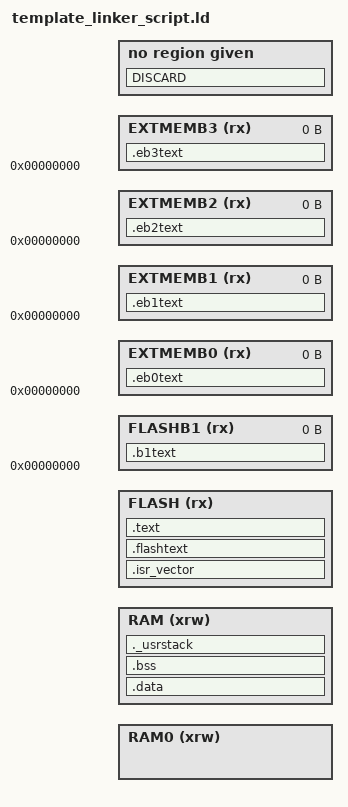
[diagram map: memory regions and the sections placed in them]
__flash         = @FLASH_ORIGIN@;
__flash_size    = @FLASH_SIZE@K;
__ram           = @RAM_ORIGIN@;
__ram_size      = @RAM_SIZE@K;
__isr_ram_size  = @ISR_RAM_SIZE@;
__stack_size    = @STACK_SIZE@;
__heap_size_min = @HEAP_MIN@;

_estack  = __ram + __ram_size;
RAM0     = __ram;
RAM0_SIZ = __isr_ram_size;
RAM      = __ram + __isr_ram_size;
RAM_SIZ  = __ram_size - __isr_ram_size;

/* Entry Point */
ENTRY(Reset_Handler)

_Minimum_Stack_Size = __stack_size;


/* Memory Spaces Definitions */
MEMORY
{
    RAM0 (xrw) : ORIGIN = RAM0,    LENGTH = RAM0_SIZ
    RAM (xrw)  : ORIGIN = RAM,     LENGTH = RAM_SIZ
    FLASH (rx) : ORIGIN = __flash, LENGTH = __flash_size
    FLASHB1 (rx) : ORIGIN = 0x00000000, LENGTH = 0
    EXTMEMB0 (rx) : ORIGIN = 0x00000000, LENGTH = 0
    EXTMEMB1 (rx) : ORIGIN = 0x00000000, LENGTH = 0
    EXTMEMB2 (rx) : ORIGIN = 0x00000000, LENGTH = 0
    EXTMEMB3 (rx) : ORIGIN = 0x00000000, LENGTH = 0
}

/* Sections Definitions */
SECTIONS
{
    /* for Cortex devices, the beginning of the startup code is stored in the .isr_vector section, which goes to FLASH */
    .isr_vector :
    {
	. = ALIGN(4);
        KEEP(*(.isr_vector))            /* Startup code */
	. = ALIGN(4);
    } >FLASH
 
    /* for some STRx devices, the beginning of the startup code is stored in the .flashtext section, which goes to FLASH */
    .flashtext :
    {
	. = ALIGN(4);
        *(.flashtext)            /* Startup code */
	. = ALIGN(4);
    } >FLASH
 
    
    /* the program code is stored in the .text section, which goes to Flash */
    .text :
    {
	    . = ALIGN(4);
	    
        *(.text)                   /* remaining code */
        *(.text.*)                   /* remaining code */
        *(.rodata)                 /* read-only data (constants) */
        *(.rodata*)
        *(.glue_7)
        *(.glue_7t)

	    . = ALIGN(4);
   	 _etext = .;
	    /* This is used by the startup in order to initialize the .data secion */
   	 _sidata = _etext;
    } >FLASH
    
 

    /* This is the initialized data section
    The program executes knowing that the data is in the RAM
    but the loader puts the initial values in the FLASH (inidata).
    It is one task of the startup to copy the initial values from FLASH to RAM. */
    .data  : AT ( _sidata )
    {
	    . = ALIGN(4);
        /* This is used by the startup in order to initialize the .data secion */
        _sdata = . ;
        
        *(.data)
        *(.data.*)

	    . = ALIGN(4);
	    /* This is used by the startup in order to initialize the .data secion */
   	 _edata = . ;
    } >RAM
    
    

    /* This is the uninitialized data section */
    .bss :
    {
	    . = ALIGN(4);
        /* This is used by the startup in order to initialize the .bss secion */
        _sbss = .;
        
        *(.bss)
        *(COMMON)
        
	    . = ALIGN(4);
	    /* This is used by the startup in order to initialize the .bss secion */
   	 _ebss = . ;
    } >RAM
    
    PROVIDE ( end = _ebss );
    PROVIDE ( _end = _ebss );
    
    /* This is the user stack section 
    This is just to check that there is enough RAM left for the User mode stack
    It should generate an error if it's full.
     */
    ._usrstack :
    {
	    . = ALIGN(4);
        _susrstack = . ;
        
        . = . + _Minimum_Stack_Size ;
        
	    . = ALIGN(4);
        _eusrstack = . ;
    } >RAM
    

   
    /* this is the FLASH Bank1 */
    /* the C or assembly source must explicitly place the code or data there
    using the "section" attribute */
    .b1text :
    {
        *(.b1text)                   /* remaining code */
        *(.b1rodata)                 /* read-only data (constants) */
        *(.b1rodata*)
    } >FLASHB1
    
    /* this is the EXTMEM */
    /* the C or assembly source must explicitly place the code or data there
    using the "section" attribute */
    
    /* EXTMEM Bank0 */
    .eb0text :
    {
        *(.eb0text)                   /* remaining code */
        *(.eb0rodata)                 /* read-only data (constants) */
        *(.eb0rodata*)
    } >EXTMEMB0
    
    /* EXTMEM Bank1 */
    .eb1text :
    {
        *(.eb1text)                   /* remaining code */
        *(.eb1rodata)                 /* read-only data (constants) */
        *(.eb1rodata*)
    } >EXTMEMB1
    
    /* EXTMEM Bank2 */
    .eb2text :
    {
        *(.eb2text)                   /* remaining code */
        *(.eb2rodata)                 /* read-only data (constants) */
        *(.eb2rodata*)
    } >EXTMEMB2
    
    /* EXTMEM Bank0 */
    .eb3text :
    {
        *(.eb3text)                   /* remaining code */
        *(.eb3rodata)                 /* read-only data (constants) */
        *(.eb3rodata*)
    } >EXTMEMB3
    
    
    
    /* after that it's only debugging information. */
    
    /* remove the debugging information from the standard libraries */
    DISCARD :
    {
        libc.a ( * )
        libm.a ( * )
        libgcc.a ( * )
    }

    /* Stabs debugging sections.  */
    .stab          0 : { *(.stab) }
    .stabstr       0 : { *(.stabstr) }
    .stab.excl     0 : { *(.stab.excl) }
    .stab.exclstr  0 : { *(.stab.exclstr) }
    .stab.index    0 : { *(.stab.index) }
    .stab.indexstr 0 : { *(.stab.indexstr) }
    .comment       0 : { *(.comment) }
    /* DWARF debug sections.
       Symbols in the DWARF debugging sections are relative to the beginning
       of the section so we begin them at 0.  */
    /* DWARF 1 */
    .debug          0 : { *(.debug) }
    .line           0 : { *(.line) }
    /* GNU DWARF 1 extensions */
    .debug_srcinfo  0 : { *(.debug_srcinfo) }
    .debug_sfnames  0 : { *(.debug_sfnames) }
    /* DWARF 1.1 and DWARF 2 */
    .debug_aranges  0 : { *(.debug_aranges) }
    .debug_pubnames 0 : { *(.debug_pubnames) }
    /* DWARF 2 */
    .debug_info     0 : { *(.debug_info .gnu.linkonce.wi.*) }
    .debug_abbrev   0 : { *(.debug_abbrev) }
    .debug_line     0 : { *(.debug_line) }
    .debug_frame    0 : { *(.debug_frame) }
    .debug_str      0 : { *(.debug_str) }
    .debug_loc      0 : { *(.debug_loc) }
    .debug_macinfo  0 : { *(.debug_macinfo) }
    /* SGI/MIPS DWARF 2 extensions */
    .debug_weaknames 0 : { *(.debug_weaknames) }
    .debug_funcnames 0 : { *(.debug_funcnames) }
    .debug_typenames 0 : { *(.debug_typenames) }
    .debug_varnames  0 : { *(.debug_varnames) }
}
